# H5 register map
Vendor: Allwinner; Series: H5; File version: 0.1
CPU: 0, little endian, MPU, no FPU, 0 interrupt priority bits
Registers are 32-bit, read-write, reset 0x0 unless marked. A register's access mark holds for its fields unless they carry their own. Offsets are from the block's base; [hi:lo] are bit positions; {n}, {i} and the like mark numbered series.

## RTC
Base 0x01F00000
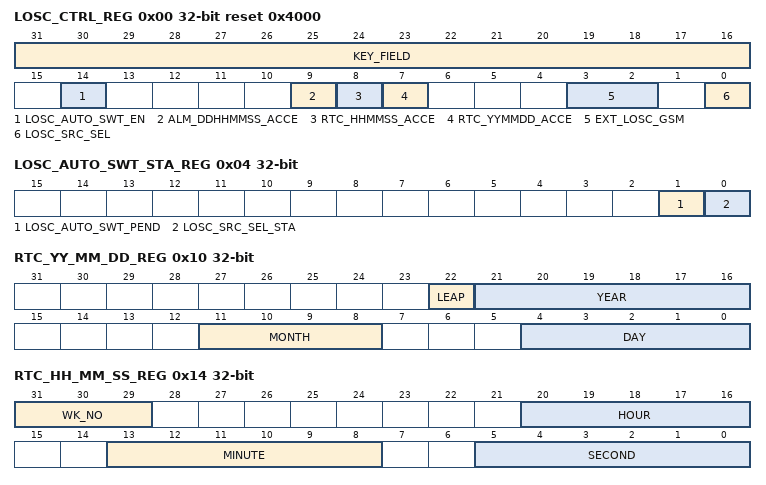
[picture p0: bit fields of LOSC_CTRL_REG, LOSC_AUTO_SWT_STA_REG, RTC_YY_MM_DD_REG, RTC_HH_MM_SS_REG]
0x00 LOSC_CTRL_REG reset 0x4000 — Low Oscillator Control Register
  [31:16] KEY_FIELD wo — Key Field. This field should be filled with 0x16AA, and then the bit 0 can be written with the new value.
  [14] LOSC_AUTO_SWT_EN — LOSC auto switch enable. 0: Disable 1: Enable.
    0=Disable; 1=Enable
  [9] ALM_DDHHMMSS_ACCE — ALARM DD-HH-MM-SS access. After writing the Alarm 1 Week HH-MM-SS Register , this bit is set and it will be cleared until the real writing operation is finished.
  [8] RTC_HHMMSS_ACCE — RTC HH-MM-SS access. After writing the RTC HH-MM-SS Register , this bit is set and it will be cleared until the real writing operation is finished. After writing the RTC HH-MM-SS Register , the RTC HH-MM-SS Register will be refreshed for at most one second.
  [7] RTC_YYMMDD_ACCE — RTC YY-MM-DD access. After writing the RTC YY-MM-DD Register , this bit is set and it will be cleared until the real writing operation is finished. After writing the RTC YY-MM-DD Register , the RTC YY-MM-DD Register will be refreshed for at most one second.
  [3:2] EXT_LOSC_GSM — External 32768Hz Crystal GSM. 00: Low 01: / 10: / 11 High
    0=Low; 2=_slash_ (/ 11 High)
  [0] LOSC_SRC_SEL — LOSC Clo k sou e Sele t. N is the alue of Internal OSC Clock Prescalar Register . 0: InternalOSC /32/ N 1: External 32.768kHz OSC. (InternalOSC = 16MHz)
    0=InternalOSC /32/ N; 1=External 32.768kHz OSC. (InternalOSC = 16MHz)
0x04 LOSC_AUTO_SWT_STA_REG — LOSC Auto Switch Status Register
  [1] LOSC_AUTO_SWT_PEND write-1-clears — LOSC auto switch pending. 0: No effect 1: Auto switches pending Setting 1 to this bit will clear it.
    0=No_effect; 1=Auto switches pending Setting 1 to this bit will clear it
  [0] LOSC_SRC_SEL_STA ro — Che ki g LOSC Clo k Sou e Status. N is the alue of Internal OSC Clock Prescalar Register . 0: InternalOSC /32/ N 1: External 32.768KHz OSC (InternalOSC = 16MHz)
    0=InternalOSC /32/ N; 1=External 32.768KHz OSC (InternalOSC = 16MHz)
0x08 INTOSC_CLK_PRESCAL_REG reset 0xF — Internal OSC Clock Prescalar Register
  [15:0] INTOSC_CLK_PRESCAL — Internal OSC Clock Prescalar value N. 0x000: 1 0x001: 2 0x002: 3 ...... 0x1F: 32
    0=_1; 1=_2; 2=_3; 31=_32
0x10 RTC_YY_MM_DD_REG (reset mask 0x400000) — RTC Year-Month-Day Register
  [22] LEAP — Leap Year. 0: Not 1: Leap year. This bit can not set by hardware. It should be set or cleared by software.
    0=Not; 1=Leap year. This bit can not set by hardware. It should be set or cleared by software.
  [21:16] YEAR — Year. Range from 0~63.
  [11:8] MONTH — Month. Range from 1~12.
  [4:0] DAY — Day. Range from 1~31.
0x14 RTC_HH_MM_SS_REG (reset mask 0xE0000000) — RTC Hour-Minute-Second Register
  [31:29] WK_NO — Week number. 000: Monday 001: Tuesday 010: Wednesday 011: Thursday 100: Friday 101: Saturday 110: Sunday 111: /
    0=Monday; 1=Tuesday; 2=Wednesday; 3=Thursday; 4=Friday; 5=Saturday; 6=Sunday
  [20:16] HOUR — Range from 0~23
  [13:8] MINUTE — Range from 0~59
  [5:0] SECOND — Range from 0~59
0x20 ALARM0_COUNTER_REG — Alarm 0 Counter Register
  [31:0] ALARM0_COUNTER — Alarm 0 Counter is based on second.
0x24 ALARM0_CUR_VLU_REG reset not defined — Alarm 0 Counter Current Value Register
  [31:0] ALARM0_CUR_VLU ro — Check Alarm 0 Counter Current Values.
0x28 ALARM0_ENABLE_REG — Alarm 0 Enable Register
  [0] ALM_0_EN — Alarm 0 Enable. If this it is set to , th e valid bits of Alarm 0 Counter Register will down ou t to ze o, a d the ala pe di g it ill e set to . 0: Disable 1: Enable
    0=Disable; 1=Enable
0x2C ALARM0_IRQ_EN — Alarm 0 IRQ Enable Register
  [0] ALARM0_IRQ_EN — Alarm 0 IRQ Enable. 0: Disable 1: Enable
    0=Disable; 1=Enable
0x30 ALARM0_IRQ_STA_REG — Alarm 0 IRQ Status Register
  [0] ALARM0_IRQ_PEND write-1-clears — Alarm 0 IRQ Pending bit. 0: No effect 1: Pending, alarm 0 counter value is reached If alarm 0 irq enable is set to 1, the pending bit will be sent to the interrupt controller.
    0=No_effect; 1=Pending, alarm 0 counter value is reached If alarm 0 irq enable is set to 1, the pending bit will be sent to the interrupt controller
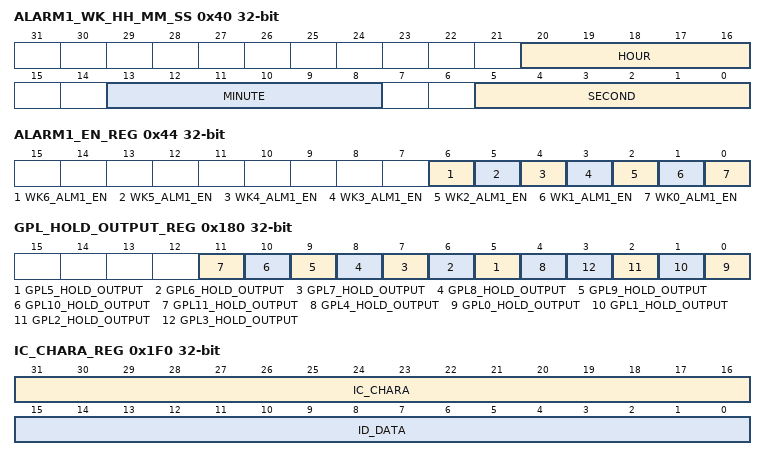
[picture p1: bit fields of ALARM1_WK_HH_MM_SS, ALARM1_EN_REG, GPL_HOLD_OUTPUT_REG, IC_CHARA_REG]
0x40 ALARM1_WK_HH_MM_SS reset not defined
  [20:16] HOUR — Range from 0~23.
  [13:8] MINUTE — Range from 0~59.
  [5:0] SECOND — Range from 0~59.
0x44 ALARM1_EN_REG
  [6] WK6_ALM1_EN — Week 6 (Sunday) Alarm 1 Enable. 0: Disable 1: Enable If this it is set to , o l he the alid its of Alarm 1 Week HH-MM-SS Register is equal to the bit[20:0] of RTC HH-MM-SS Register and the bit[31:29] of RTC HH-MM-SS Register is 6, the week 6 alarm irq pending bit ill e set to .
    0=Disable; 1=Enable If this it is set to , o l he the alid its of Alarm 1 Week HH-MM-SS Register is equal to the bit[20:0] of RTC HH-MM-SS Register and the bit[31:29] of RTC HH-MM-SS Register is 6, the week 6 alarm irq pending bit ill e set to 
  [5] WK5_ALM1_EN — Week 5 (Saturday) Alarm 1 Enable. 0: Disable 1: Enable If this it is set to , o l he the alid its of Alarm 1 Week HH-MM-SS Register is equal to the bit[20:0] of RTC HH-MM-SS Register and the bit[31:29] of RTC HH-MM-SS Register is 5, the week 5 alarm irq pending bit ill e set to .
    0=Disable; 1=Enable If this it is set to , o l he the alid its of Alarm 1 Week HH-MM-SS Register is equal to the bit[20:0] of RTC HH-MM-SS Register and the bit[31:29] of RTC HH-MM-SS Register is 5, the week 5 alarm irq pending bit ill e set to 
  [4] WK4_ALM1_EN — Week 4 (Friday) Alarm 1 Enable. 0: Disable 1: Enable If this it is set to , o l he the alid its of Alarm 1 Week HH-MM-SS Register is equal to the bit[20:0] of RTC HH-MM-SS Register and the register bit[31:29] of RTC HH-MM-SS Register is 4, the week 4 alarm irq pending bit ill e set to .
    0=Disable; 1=Enable If this it is set to , o l he the alid its of Alarm 1 Week HH-MM-SS Register is equal to the bit[20:0] of RTC HH-MM-SS Register and the register bit[31:29] of RTC HH-MM-SS Register is 4, the week 4 alarm irq pending bit ill e set to 
  [3] WK3_ALM1_EN — Week 3 (Thursday) Alarm 1 Enable. 0: Disable 1: Enable If this it is set to , o l he the alid its of Alarm 1 Week HH-MM-SS Register is equal to the bit[20:0] of RTC HH-MM-SS Register and the bit[31:29] of RTC HH-MM-SS Register is 3, the week 3 alarm irq pending bit ill e set to .
    0=Disable; 1=Enable If this it is set to , o l he the alid its of Alarm 1 Week HH-MM-SS Register is equal to the bit[20:0] of RTC HH-MM-SS Register and the bit[31:29] of RTC HH-MM-SS Register is 3, the week 3 alarm irq pending bit ill e set to 
  [2] WK2_ALM1_EN — Week 2 (Wednesday) Alarm 1 Enable. 0: Disable 1: Enable If this it is set to , o l he the alid its of Alarm 1 Week HH-MM-SS Register is equal to the bit[20:0] of RTC HH-MM-SS Register and the bit[31:29] of RTC HH-MM-SS Register is 2, the week 2 alarm irq pending bit ill e set to .
    0=Disable; 1=Enable If this it is set to , o l he the alid its of Alarm 1 Week HH-MM-SS Register is equal to the bit[20:0] of RTC HH-MM-SS Register and the bit[31:29] of RTC HH-MM-SS Register is 2, the week 2 alarm irq pending bit ill e set to 
  [1] WK1_ALM1_EN — Week 1 (Tuesday) Alarm 1 Enable. 0: Disable 1: Enable If this it is set to , o l he the alid its of Alarm 1 Week HH-MM-SS Register is equal to the bit[20:0] of RTC HH-MM-SS Register and the bit[31:29] of RTC HH-MM-SS Register is 1, the week 1 alarm irq pending bit ill e set to .
    0=Disable; 1=Enable If this it is set to , o l he the alid its of Alarm 1 Week HH-MM-SS Register is equal to the bit[20:0] of RTC HH-MM-SS Register and the bit[31:29] of RTC HH-MM-SS Register is 1, the week 1 alarm irq pending bit ill e set to 
  [0] WK0_ALM1_EN — Week 0 (Monday) Alarm 1 Enable. 0: Disable 1: Enable If this bi t is set to , o l he the alid its of Alarm 1 Week HH-MM-SS Register is equal to the bit[20:0] of RTC HH-MM-SS Register and the bit[31:29] of RTC HH-MM-SS Register is 0, the week 0 alarm irq pending bit ill e set to .
    0=Disable; 1=Enable If this bi t is set to , o l he the alid its of Alarm 1 Week HH-MM-SS Register is equal to the bit[20:0] of RTC HH-MM-SS Register and the bit[31:29] of RTC HH-MM-SS Register is 0, the week 0 alarm irq pending bit ill e set to 
0x48 ALARM1_IRQ_EN — Alarm 1 IRQ Enable Register
  [0] ALARM1_IRQ_EN — Alarm 1 IRQ Enable. 0: Disable 1: Enable
    0=Disable; 1=Enable
0x4C ALARM1_IRQ_STA_REG — Alarm 1 IRQ Status Register
  [0] ALARM1_WEEK_IRQ_PEND write-1-clears — Alarm 1 Week (0/1/2/3/4/5/6) IRQ Pending. 0: No effect 1: Pending, week counter value is reached If alarm 1 week irq enable is set to 1, the pending bit will be sent to the interrupt controller.
    0=No_effect; 1=Pending, week counter value is reached If alarm 1 week irq enable is set to 1, the pending bit will be sent to the interrupt controller
0x50 ALARM_CONFIG_REG — Alarm Configuration Register
  [0] ALARM_WAKEUP — Configuration of alarm wake up output. 0: Disable alarm wake up output 1: Enable alarm wake up output
    0=Disable alarm wake up output; 1=Enable alarm wake up output
0x60 LOSC_OUT_GATING_REG — LOSC Output Gating Register
  [0] LOSC_OUT_GATING — Configuration of LOSC output, and without LOSC output by default. 0: Enable LOSC output gating 1: Disable LOSC output gating
    0=Enable LOSC output gating; 1=Disable LOSC output gating
{0x100+4i} GP_DATA_REGN[{i}] (i=0..7) — GP_DATA_REGN[{i}]
  [31:0] GP_DATA — Data [31:0].
0x180 GPL_HOLD_OUTPUT_REG — GPL Hold Output Register
  [all] fields
    0=Hold_disable; 1=Hold_enable
  [n] GPL{n}_HOLD_OUTPUT (n=5..11) — Hold the output of GPIOL{n} when the power of system is changing. The output must be low level (0) or high level (1) or High-Z; any other outputs may not hold on. 0: Hold disable 1: Hold enable
  [4] GPL4_HOLD_OUTPUT — Hold the output of GPIOL4 when the power of system is changing. The output must be low level (0) or high level (1) or High-Z; any other output may not hold on. 0: Hold disable 1: Hold enable
  [n] GPL{n}_HOLD_OUTPUT (n=0..3) — Hold the output of GPIOL{n} when the power of system is changing. The output must be low level (0) or high level (1) or High-Z; any other outputs may not hold on. 0: Hold disable 1: Hold enable
0x190 RTC_VIO_REG reset 0x4
  [2:0] RTC_VIO_REGU — These bits are useful for regulating the RTC-VIO from 0.776V to 1.535V. 000: 0.235 * VCC-RTC ( 0.776V) 001: 0.265 * VCC-RTC (0.8745V) 010: 0.3 * VCC-RTC (0.99V) 011: 0.335 * VCC-RTC (1.1055V) 100: 0.365 * VCC-RTC (1.205V) 101: 0.4 * VCC-RTC (1.32V) 110: 0.435 * VCC-RTC (1.4355V) 111: 0.465 * VCC-RTC (1.535V) Note: VCC-RTC = 3.3V
    0=_0_point_235 (0.235 * VCC-RTC ( 0.776V)); 1=_0_point_265 (0.265 * VCC-RTC (0.8745V)); 2=_0_point_3 (0.3 * VCC-RTC (0.99V)); 3=_0_point_335 (0.335 * VCC-RTC (1.1055V)); 4=_0_point_365 (0.365 * VCC-RTC (1.205V)); 5=_0_point_4 (0.4 * VCC-RTC (1.32V)); 6=_0_point_435 (0.435 * VCC-RTC (1.4355V)); 7=_0_point_465 (0.465 * VCC-RTC (1.535V) Note: VCC-RTC = 3.3V)
0x1F0 IC_CHARA_REG — IC Characteristic Register
  [31:16] IC_CHARA — Key Field. The field should be written to 0x16AA. Writing any other value in this field aborts the write operation.
  [15:0] ID_DATA — Return 0x16AA only if the KEY_FIELD is set as 0x16AA when read those bits, otherwise return 0x0.
0x210 CRY_CONFIG_REG — Crypto Configuration Register
  [15:0] KEY_FIELD
0x214 CRY_KEY_REG — Crypto Key Register
  [31:0] CRY_KEY — Crypto Key
0x218 CRY_EN_REG — Crypto Enable Register
  [0] CRY_EN — Crypto Enable
